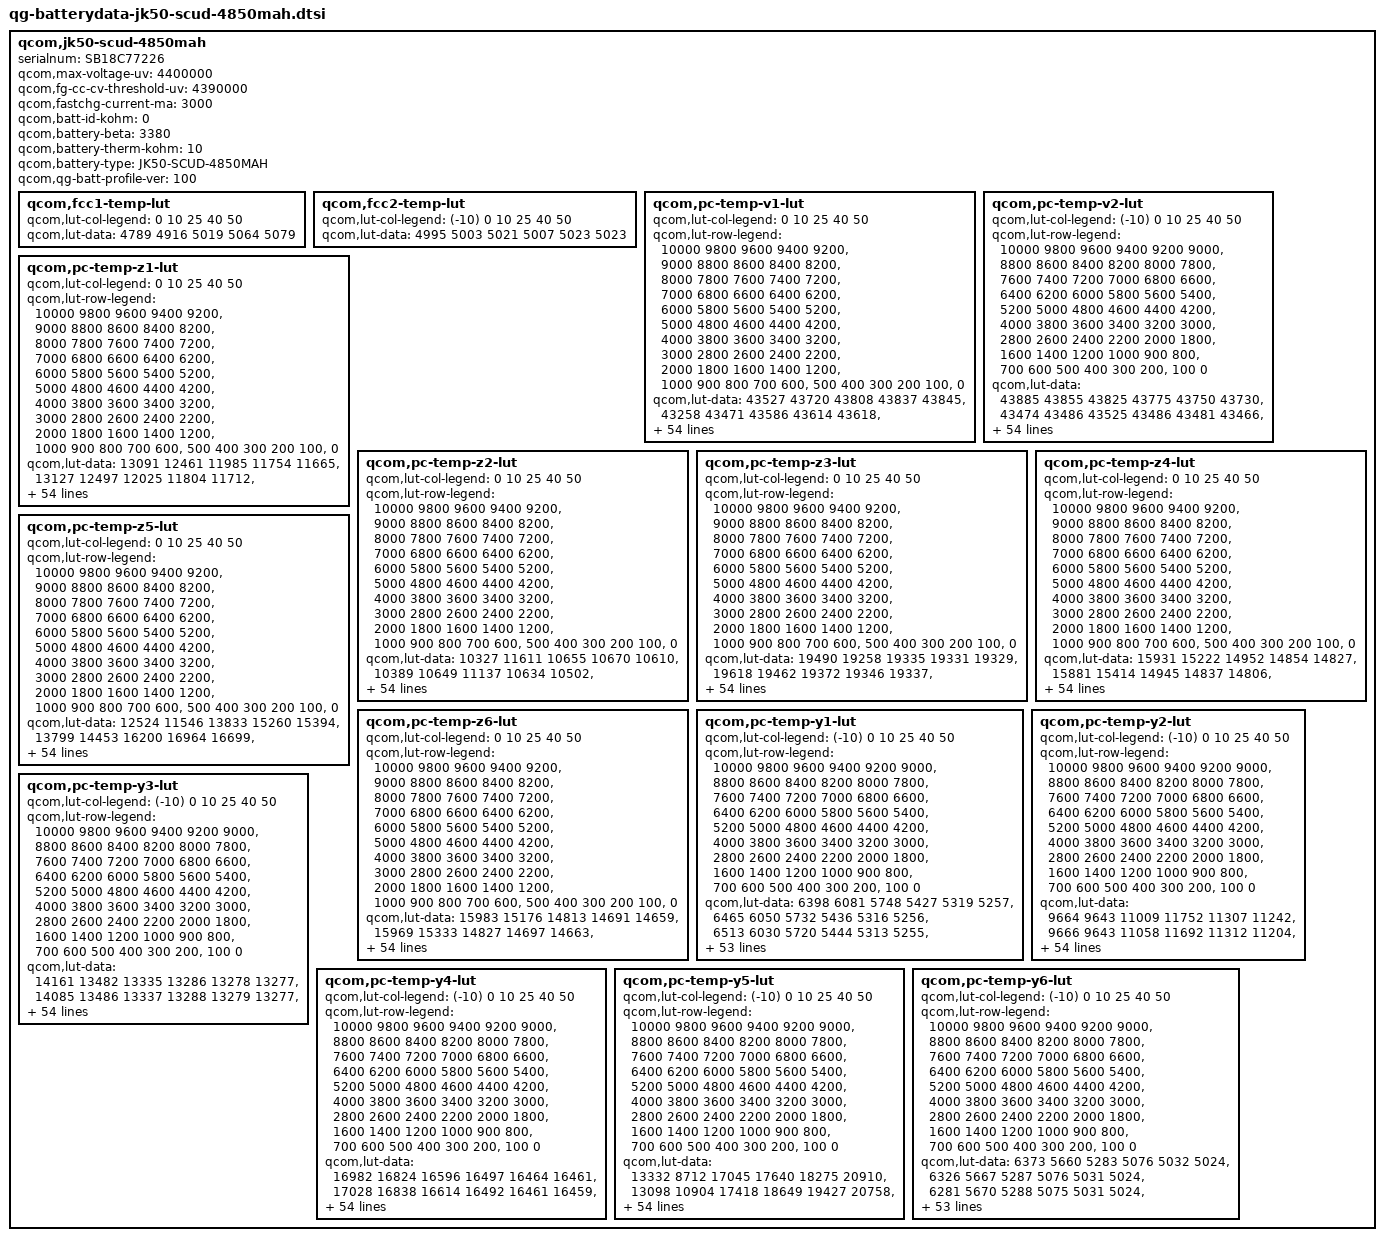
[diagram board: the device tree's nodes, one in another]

qcom,jk50-scud-4850mah {
    /* 4487667_P270AE_SCUD_4850mAH_PMI632_averaged_MasterSlave_Apr8th2020 */
    serialnum = "SB18C77226";
    qcom,max-voltage-uv = <4400000>;
    qcom,fg-cc-cv-threshold-uv = <4390000>;
    qcom,fastchg-current-ma = <3000>;
    qcom,batt-id-kohm = <0>;
    qcom,battery-beta = <3380>;
    qcom,battery-therm-kohm = <10>;
    qcom,battery-type = "JK50-SCUD-4850MAH";
    qcom,qg-batt-profile-ver = <100>;

	qcom,fcc1-temp-lut {
		qcom,lut-col-legend = <0 10 25 40 50>;
		qcom,lut-data = <4789 4916 5019 5064 5079>;
	};

	qcom,fcc2-temp-lut {
		qcom,lut-col-legend = <(-10) 0 10 25 40 50>;
		qcom,lut-data = <4995 5003 5021 5007 5023 5023>;
	};

	qcom,pc-temp-v1-lut {
		qcom,lut-col-legend = <0 10 25 40 50>;
		qcom,lut-row-legend = <10000 9800 9600 9400 9200>,
			<9000 8800 8600 8400 8200>,
			<8000 7800 7600 7400 7200>,
			<7000 6800 6600 6400 6200>,
			<6000 5800 5600 5400 5200>,
			<5000 4800 4600 4400 4200>,
			<4000 3800 3600 3400 3200>,
			<3000 2800 2600 2400 2200>,
			<2000 1800 1600 1400 1200>,
			<1000 900 800 700 600>,
			<500 400 300 200 100>,
			<0>;
		qcom,lut-data = <43527 43720 43808 43837 43845>,
			<43258 43471 43586 43614 43618>,
			<43002 43216 43362 43390 43400>,
			<42761 42969 43124 43158 43170>,
			<42532 42728 42882 42923 42937>,
			<42311 42495 42638 42687 42703>,
			<42098 42267 42393 42451 42467>,
			<41890 42046 42156 42216 42231>,
			<41681 41831 41927 41986 42000>,
			<41477 41616 41703 41759 41771>,
			<41296 41407 41482 41532 41545>,
			<41144 41224 41270 41309 41323>,
			<40970 41074 41086 41094 41105>,
			<40688 40898 40925 40893 40895>,
			<40345 40606 40727 40693 40690>,
			<40100 40268 40429 40483 40490>,
			<39934 40057 40147 40274 40297>,
			<39796 39919 39991 40092 40114>,
			<39671 39796 39877 39933 39942>,
			<39561 39678 39747 39775 39774>,
			<39446 39558 39599 39616 39613>,
			<39327 39402 39425 39445 39447>,
			<39205 39202 39159 39222 39237>,
			<39083 39004 38872 38955 38980>,
			<38959 38805 38724 38778 38797>,
			<38833 38632 38641 38676 38689>,
			<38696 38534 38565 38588 38597>,
			<38570 38469 38486 38491 38494>,
			<38481 38415 38410 38397 38393>,
			<38410 38366 38339 38313 38304>,
			<38357 38324 38272 38239 38226>,
			<38318 38284 38212 38171 38156>,
			<38286 38247 38160 38113 38098>,
			<38256 38213 38112 38059 38043>,
			<38230 38184 38071 38007 37983>,
			<38200 38153 38033 37957 37921>,
			<38169 38119 37993 37907 37860>,
			<38133 38081 37954 37859 37806>,
			<38084 38029 37903 37802 37743>,
			<38017 37944 37821 37719 37655>,
			<37933 37839 37715 37613 37545>,
			<37811 37721 37601 37499 37427>,
			<37668 37584 37472 37368 37295>,
			<37520 37421 37317 37215 37145>,
			<37370 37273 37170 37074 37010>,
			<37258 37172 37081 36991 36932>,
			<37219 37156 37052 36962 36906>,
			<37188 37131 37037 36945 36886>,
			<37162 37107 37019 36927 36865>,
			<37121 37068 36977 36873 36804>,
			<36931 36868 36759 36630 36538>,
			<36501 36442 36338 36197 36097>,
			<35935 35872 35773 35623 35525>,
			<35166 35095 35000 34839 34741>,
			<33969 33890 33810 33627 33524>,
			<30000 30000 30000 30000 30000>;
	};

	qcom,pc-temp-v2-lut {
		qcom,lut-col-legend = <(-10) 0 10 25 40 50>;
		qcom,lut-row-legend = <10000 9800 9600 9400 9200 9000>,
			<8800 8600 8400 8200 8000 7800>,
			<7600 7400 7200 7000 6800 6600>,
			<6400 6200 6000 5800 5600 5400>,
			<5200 5000 4800 4600 4400 4200>,
			<4000 3800 3600 3400 3200 3000>,
			<2800 2600 2400 2200 2000 1800>,
			<1600 1400 1200 1000 900 800>,
			<700 600 500 400 300 200>,
			<100 0>;
		qcom,lut-data = <43885 43855 43825 43775 43750 43730>,
			<43474 43486 43525 43486 43481 43466>,
			<43101 43156 43244 43213 43220 43210>,
			<42770 42871 42981 42957 42972 42964>,
			<42473 42624 42736 42717 42733 42728>,
			<42205 42382 42495 42481 42497 42493>,
			<41960 42137 42255 42245 42261 42259>,
			<41736 41892 42019 42013 42027 42026>,
			<41509 41621 41791 41785 41798 41796>,
			<41289 41340 41569 41562 41571 41568>,
			<41193 41168 41355 41340 41347 41344>,
			<41169 41084 41147 41118 41127 41125>,
			<41140 40990 40949 40907 40912 40909>,
			<40792 40780 40773 40726 40711 40701>,
			<40103 40467 40599 40555 40515 40498>,
			<39725 40162 40365 40343 40318 40304>,
			<39532 39838 40047 40073 40119 40118>,
			<39362 39565 39780 39851 39934 39939>,
			<39182 39386 39612 39721 39773 39774>,
			<39009 39231 39462 39606 39613 39608>,
			<38840 39046 39273 39425 39417 39417>,
			<38671 38841 39059 39173 39192 39202>,
			<38532 38659 38872 38951 38984 38998>,
			<38418 38495 38711 38767 38791 38799>,
			<38324 38357 38569 38610 38624 38626>,
			<38250 38254 38445 38486 38497 38496>,
			<38189 38172 38335 38383 38391 38389>,
			<38132 38109 38232 38287 38292 38289>,
			<38080 38058 38136 38197 38202 38197>,
			<38031 38015 38050 38114 38120 38113>,
			<37982 37974 37975 38040 38048 38040>,
			<37933 37936 37910 37971 37982 37972>,
			<37884 37898 37865 37908 37918 37908>,
			<37836 37861 37831 37850 37856 37848>,
			<37785 37822 37798 37795 37789 37779>,
			<37731 37781 37763 37741 37710 37689>,
			<37672 37737 37726 37686 37627 37592>,
			<37607 37684 37681 37625 37544 37495>,
			<37536 37622 37628 37559 37459 37397>,
			<37461 37550 37561 37486 37378 37310>,
			<37383 37467 37469 37404 37302 37236>,
			<37304 37367 37359 37308 37213 37148>,
			<37224 37244 37232 37191 37101 37037>,
			<37151 37109 37090 37057 36961 36895>,
			<37068 36991 36961 36929 36848 36791>,
			<36983 36913 36901 36883 36815 36760>,
			<36938 36889 36875 36868 36803 36748>,
			<36884 36860 36851 36854 36787 36735>,
			<36807 36816 36811 36827 36763 36705>,
			<36680 36728 36722 36764 36676 36605>,
			<36437 36508 36478 36532 36379 36279>,
			<36026 36071 36010 36064 35878 35774>,
			<35432 35443 35368 35447 35228 35115>,
			<34574 34550 34458 34598 34326 34193>,
			<33175 33170 33140 33334 32948 32812>,
			<28986 28473 27920 28444 28011 28001>;
	};

	qcom,pc-temp-z1-lut {
		qcom,lut-col-legend = <0 10 25 40 50>;
		qcom,lut-row-legend = <10000 9800 9600 9400 9200>,
			<9000 8800 8600 8400 8200>,
			<8000 7800 7600 7400 7200>,
			<7000 6800 6600 6400 6200>,
			<6000 5800 5600 5400 5200>,
			<5000 4800 4600 4400 4200>,
			<4000 3800 3600 3400 3200>,
			<3000 2800 2600 2400 2200>,
			<2000 1800 1600 1400 1200>,
			<1000 900 800 700 600>,
			<500 400 300 200 100>,
			<0>;
		qcom,lut-data = <13091 12461 11985 11754 11665>,
			<13127 12497 12025 11804 11712>,
			<13151 12516 12024 11806 11719>,
			<13165 12519 12036 11801 11720>,
			<13170 12509 12044 11798 11719>,
			<13163 12499 12040 11796 11717>,
			<13148 12496 12032 11793 11717>,
			<13138 12501 12026 11790 11716>,
			<13144 12505 12021 11789 11717>,
			<13150 12503 12018 11788 11719>,
			<13150 12498 12020 11787 11721>,
			<13157 12494 12023 11787 11722>,
			<13162 12489 12022 11786 11722>,
			<13130 12483 12017 11785 11721>,
			<13073 12460 12011 11784 11720>,
			<13056 12430 12001 11782 11720>,
			<13055 12424 11993 11781 11720>,
			<13055 12425 11996 11781 11720>,
			<13059 12428 12004 11783 11722>,
			<13066 12437 12010 11784 11722>,
			<13067 12450 12014 11784 11722>,
			<13058 12457 12017 11784 11722>,
			<13048 12462 12020 11785 11722>,
			<13046 12465 12023 11787 11723>,
			<13046 12469 12025 11788 11725>,
			<13049 12473 12028 11791 11726>,
			<13060 12477 12030 11794 11727>,
			<13070 12485 12031 11797 11730>,
			<13072 12491 12032 11801 11733>,
			<13071 12497 12036 11804 11736>,
			<13073 12501 12042 11808 11738>,
			<13086 12503 12047 11812 11741>,
			<13101 12503 12053 11815 11744>,
			<13106 12503 12057 11818 11747>,
			<13110 12505 12058 11823 11751>,
			<13117 12508 12059 11827 11755>,
			<13133 12511 12062 11831 11758>,
			<13148 12516 12070 11833 11760>,
			<13158 12523 12077 11836 11763>,
			<13178 12540 12078 11840 11766>,
			<13191 12556 12079 11844 11769>,
			<13201 12563 12081 11848 11772>,
			<13207 12567 12087 11852 11776>,
			<13211 12569 12093 11857 11778>,
			<13202 12573 12104 11863 11780>,
			<13197 12571 12106 11866 11783>,
			<13165 12566 12106 11869 11783>,
			<13192 12574 12106 11870 11784>,
			<13186 12571 12103 11870 11787>,
			<13194 12588 12114 11874 11792>,
			<13185 12574 12115 11881 11798>,
			<13221 12597 12127 11889 11805>,
			<13214 12609 12142 11901 11818>,
			<13253 12651 12178 11918 11834>,
			<13253 12651 12178 11918 11834>,
			<13253 12651 12178 11918 11834>;
	};

	qcom,pc-temp-z2-lut {
		qcom,lut-col-legend = <0 10 25 40 50>;
		qcom,lut-row-legend = <10000 9800 9600 9400 9200>,
			<9000 8800 8600 8400 8200>,
			<8000 7800 7600 7400 7200>,
			<7000 6800 6600 6400 6200>,
			<6000 5800 5600 5400 5200>,
			<5000 4800 4600 4400 4200>,
			<4000 3800 3600 3400 3200>,
			<3000 2800 2600 2400 2200>,
			<2000 1800 1600 1400 1200>,
			<1000 900 800 700 600>,
			<500 400 300 200 100>,
			<0>;
		qcom,lut-data = <10327 11611 10655 10670 10610>,
			<10389 10649 11137 10634 10502>,
			<10422 10668 12508 10705 10487>,
			<10425 10685 12606 10742 10605>,
			<10424 10664 12430 10744 10603>,
			<10427 10629 11777 10731 10598>,
			<10432 10599 10968 10702 10605>,
			<10434 10573 10755 10669 10605>,
			<10430 10552 10717 10622 10575>,
			<10422 10537 10707 10580 10528>,
			<10417 10525 10899 10584 10507>,
			<10415 10549 11126 10604 10505>,
			<10412 10721 11181 10605 10500>,
			<10372 10842 11344 10531 10466>,
			<10307 10761 11389 10470 10422>,
			<10290 10626 11088 10516 10390>,
			<10296 10601 10788 10597 10362>,
			<10307 10615 10748 10596 10359>,
			<10327 10637 10733 10508 10380>,
			<10358 10675 10736 10459 10407>,
			<10381 10722 10786 10558 10441>,
			<10397 10757 10829 10678 10475>,
			<10411 10787 10840 10647 10480>,
			<10425 10798 10842 10527 10477>,
			<10440 10774 10827 10487 10478>,
			<10457 10744 10782 10516 10499>,
			<10479 10747 10760 10568 10537>,
			<10502 10767 10793 10718 10641>,
			<10521 10777 10838 10919 10792>,
			<10537 10777 10857 10935 10804>,
			<10552 10777 10869 10826 10671>,
			<10562 10781 10876 10731 10530>,
			<10573 10790 10883 10664 10404>,
			<10588 10802 10889 10621 10312>,
			<10610 10817 10895 10623 10318>,
			<10636 10835 10905 10640 10367>,
			<10673 10852 10918 10664 10420>,
			<10707 10869 10938 10720 10479>,
			<10645 10887 10964 10781 10537>,
			<10407 10911 11015 10830 10583>,
			<10300 10933 11065 10872 10622>,
			<10337 10945 11067 10896 10645>,
			<10379 10957 11058 10917 10663>,
			<10127 10987 11064 10931 10704>,
			<10154 11156 11103 10920 10727>,
			<10555 11339 11168 10784 10601>,
			<10427 11087 11164 10779 10604>,
			<10647 16175 11150 10794 10608>,
			<10616 12280 11151 10834 10665>,
			<10602 11569 11225 10941 10777>,
			<10594 11472 11279 10867 10597>,
			<10227 11135 11216 10661 10387>,
			<10074 11040 11194 10600 10302>,
			<9765 10768 11064 10537 10252>,
			<9765 10768 11064 10537 10252>,
			<9765 10768 11064 10537 10252>;
	};

	qcom,pc-temp-z3-lut {
		qcom,lut-col-legend = <0 10 25 40 50>;
		qcom,lut-row-legend = <10000 9800 9600 9400 9200>,
			<9000 8800 8600 8400 8200>,
			<8000 7800 7600 7400 7200>,
			<7000 6800 6600 6400 6200>,
			<6000 5800 5600 5400 5200>,
			<5000 4800 4600 4400 4200>,
			<4000 3800 3600 3400 3200>,
			<3000 2800 2600 2400 2200>,
			<2000 1800 1600 1400 1200>,
			<1000 900 800 700 600>,
			<500 400 300 200 100>,
			<0>;
		qcom,lut-data = <19490 19258 19335 19331 19329>,
			<19618 19462 19372 19346 19337>,
			<19688 19511 19386 19370 19345>,
			<19707 19546 19413 19384 19371>,
			<19718 19552 19430 19389 19378>,
			<19717 19554 19434 19393 19384>,
			<19703 19554 19436 19398 19391>,
			<19686 19550 19436 19400 19394>,
			<19675 19544 19436 19399 19394>,
			<19663 19540 19435 19396 19393>,
			<19648 19534 19439 19393 19391>,
			<19624 19532 19441 19389 19386>,
			<19609 19531 19441 19384 19381>,
			<19639 19530 19439 19375 19375>,
			<19696 19530 19436 19369 19371>,
			<19709 19530 19433 19371 19368>,
			<19674 19525 19428 19375 19365>,
			<19634 19501 19417 19374 19362>,
			<19608 19481 19400 19365 19358>,
			<19586 19472 19394 19359 19355>,
			<19580 19465 19393 19358 19352>,
			<19581 19469 19392 19357 19349>,
			<19583 19491 19397 19356 19344>,
			<19588 19504 19406 19353 19337>,
			<19600 19505 19405 19348 19332>,
			<19611 19505 19393 19338 19329>,
			<19624 19505 19387 19332 19327>,
			<19633 19503 19387 19347 19347>,
			<19633 19501 19388 19376 19389>,
			<19627 19498 19393 19385 19397>,
			<19620 19495 19403 19389 19393>,
			<19610 19492 19408 19390 19387>,
			<19598 19489 19410 19385 19377>,
			<19586 19486 19411 19378 19366>,
			<19573 19484 19409 19372 19359>,
			<19561 19481 19405 19365 19353>,
			<19551 19478 19401 19360 19348>,
			<19539 19475 19396 19355 19344>,
			<19506 19472 19393 19352 19341>,
			<19436 19469 19391 19349 19339>,
			<19400 19465 19389 19347 19338>,
			<19398 19460 19386 19348 19340>,
			<19395 19454 19382 19351 19346>,
			<19303 19448 19380 19352 19349>,
			<19262 19427 19376 19351 19349>,
			<19260 19402 19361 19335 19335>,
			<19261 19300 19360 19335 19329>,
			<19260 19284 19347 19329 19323>,
			<19260 19276 19342 19325 19317>,
			<19260 19277 19336 19319 19312>,
			<19260 19281 19344 19333 19339>,
			<19261 19283 19342 19340 19350>,
			<19262 19282 19328 19341 19347>,
			<19265 19282 19325 19339 19345>,
			<19265 19282 19325 19339 19345>,
			<19265 19282 19325 19339 19345>;
	};

	qcom,pc-temp-z4-lut {
		qcom,lut-col-legend = <0 10 25 40 50>;
		qcom,lut-row-legend = <10000 9800 9600 9400 9200>,
			<9000 8800 8600 8400 8200>,
			<8000 7800 7600 7400 7200>,
			<7000 6800 6600 6400 6200>,
			<6000 5800 5600 5400 5200>,
			<5000 4800 4600 4400 4200>,
			<4000 3800 3600 3400 3200>,
			<3000 2800 2600 2400 2200>,
			<2000 1800 1600 1400 1200>,
			<1000 900 800 700 600>,
			<500 400 300 200 100>,
			<0>;
		qcom,lut-data = <15931 15222 14952 14854 14827>,
			<15881 15414 14945 14837 14806>,
			<15798 15320 15012 14863 14809>,
			<15655 15193 14945 14868 14841>,
			<15478 15100 14870 14834 14818>,
			<15353 15015 14840 14806 14795>,
			<15259 14951 14820 14783 14775>,
			<15185 14901 14798 14762 14756>,
			<15130 14862 14775 14745 14739>,
			<15085 14836 14751 14730 14724>,
			<15044 14815 14727 14718 14713>,
			<15006 14783 14703 14707 14706>,
			<14970 14730 14682 14700 14700>,
			<14932 14700 14654 14696 14695>,
			<14897 14718 14644 14692 14692>,
			<14876 14747 14680 14687 14688>,
			<14864 14752 14716 14682 14684>,
			<14853 14740 14706 14677 14679>,
			<14839 14727 14681 14670 14674>,
			<14823 14714 14673 14667 14672>,
			<14807 14703 14674 14669 14674>,
			<14789 14704 14677 14674 14679>,
			<14773 14719 14733 14709 14708>,
			<14759 14738 14820 14795 14790>,
			<14748 14780 14833 14824 14823>,
			<14744 14821 14823 14819 14816>,
			<14752 14821 14811 14810 14802>,
			<14761 14804 14795 14782 14765>,
			<14763 14786 14776 14739 14709>,
			<14764 14771 14757 14715 14689>,
			<14763 14757 14736 14699 14683>,
			<14758 14745 14721 14689 14679>,
			<14752 14734 14708 14682 14675>,
			<14749 14724 14700 14678 14672>,
			<14746 14715 14696 14678 14672>,
			<14743 14707 14693 14679 14673>,
			<14741 14700 14691 14679 14674>,
			<14740 14695 14689 14679 14674>,
			<14760 14694 14689 14679 14674>,
			<14827 14695 14693 14686 14682>,
			<14859 14697 14698 14697 14695>,
			<14856 14695 14696 14696 14696>,
			<14851 14692 14689 14688 14688>,
			<14932 14689 14687 14688 14689>,
			<14923 14681 14679 14687 14688>,
			<14878 14666 14657 14666 14665>,
			<14874 14770 14650 14660 14663>,
			<14869 14780 14651 14649 14653>,
			<14864 14782 14646 14634 14635>,
			<14859 14778 14648 14635 14632>,
			<14860 14781 14657 14652 14646>,
			<14879 14790 14669 14660 14654>,
			<14889 14796 14688 14664 14661>,
			<14903 14806 14697 14669 14665>,
			<14903 14806 14697 14669 14665>,
			<14903 14806 14697 14669 14665>;
	};

	qcom,pc-temp-z5-lut {
		qcom,lut-col-legend = <0 10 25 40 50>;
		qcom,lut-row-legend = <10000 9800 9600 9400 9200>,
			<9000 8800 8600 8400 8200>,
			<8000 7800 7600 7400 7200>,
			<7000 6800 6600 6400 6200>,
			<6000 5800 5600 5400 5200>,
			<5000 4800 4600 4400 4200>,
			<4000 3800 3600 3400 3200>,
			<3000 2800 2600 2400 2200>,
			<2000 1800 1600 1400 1200>,
			<1000 900 800 700 600>,
			<500 400 300 200 100>,
			<0>;
		qcom,lut-data = <12524 11546 13833 15260 15394>,
			<13799 14453 16200 16964 16699>,
			<14681 15700 15700 18448 17559>,
			<15223 16924 16546 19029 19341>,
			<15609 17733 17543 19666 20255>,
			<15829 18369 18660 20417 21258>,
			<15965 18977 19948 21463 22671>,
			<16084 19580 20930 22269 24080>,
			<16240 20128 21780 22659 25257>,
			<16379 20662 22770 23059 26241>,
			<16364 21340 24791 23808 26892>,
			<16142 22351 27299 24920 27595>,
			<15993 24190 30073 25214 27930>,
			<18258 26296 34719 24305 27890>,
			<22488 29020 36682 23545 27963>,
			<23442 31578 35248 25995 28668>,
			<21305 31032 32943 30570 30000>,
			<19261 26423 30266 31273 31350>,
			<18767 23733 27318 30042 32902>,
			<18496 24159 26998 29355 33810>,
			<18508 25262 30449 30951 33893>,
			<19595 30663 34482 32907 33633>,
			<21488 47924 38322 31977 31714>,
			<24104 56943 41764 28112 25756>,
			<28277 54745 40175 24218 21110>,
			<33648 50818 30592 19733 17926>,
			<43024 47257 24627 17085 16167>,
			<50585 43344 23316 18515 19521>,
			<50792 40411 22663 21827 27007>,
			<49025 38327 23450 24751 30609>,
			<46657 36834 26349 27782 32555>,
			<42588 36259 29586 30227 33272>,
			<37839 36498 33612 32132 31773>,
			<34211 37230 37229 33494 29898>,
			<30986 38331 39755 34131 30329>,
			<28602 39209 41699 34546 32060>,
			<27086 39861 41859 34573 32597>,
			<25728 40922 40763 33847 31830>,
			<23459 41115 39666 32673 30700>,
			<20113 40701 38467 30395 28449>,
			<18619 39993 36801 27651 25629>,
			<18834 37714 34474 26808 25441>,
			<19064 34611 31665 26840 26800>,
			<14011 33741 31342 27468 28023>,
			<12141 31978 32061 27651 28322>,
			<12271 29890 30794 23935 23905>,
			<12252 14462 30675 24086 21186>,
			<12229 13103 24723 23487 20712>,
			<12226 12762 23699 25108 23171>,
			<12241 12829 22199 22979 22331>,
			<12329 13054 22718 22538 26099>,
			<12222 12946 19929 20522 24429>,
			<12097 12765 16474 19155 20367>,
			<11962 12546 15615 17555 17690>,
			<11962 12546 15615 17555 17690>,
			<11962 12546 15615 17555 17690>;
	};

	qcom,pc-temp-z6-lut {
		qcom,lut-col-legend = <0 10 25 40 50>;
		qcom,lut-row-legend = <10000 9800 9600 9400 9200>,
			<9000 8800 8600 8400 8200>,
			<8000 7800 7600 7400 7200>,
			<7000 6800 6600 6400 6200>,
			<6000 5800 5600 5400 5200>,
			<5000 4800 4600 4400 4200>,
			<4000 3800 3600 3400 3200>,
			<3000 2800 2600 2400 2200>,
			<2000 1800 1600 1400 1200>,
			<1000 900 800 700 600>,
			<500 400 300 200 100>,
			<0>;
		qcom,lut-data = <15983 15176 14813 14691 14659>,
			<15969 15333 14827 14697 14663>,
			<15937 15296 14862 14721 14669>,
			<15860 15242 14842 14727 14693>,
			<15748 15192 14819 14717 14689>,
			<15662 15140 14805 14708 14685>,
			<15593 15097 14792 14699 14680>,
			<15534 15063 14779 14691 14674>,
			<15488 15034 14766 14683 14668>,
			<15449 15011 14755 14675 14661>,
			<15409 14993 14746 14668 14655>,
			<15366 14969 14738 14661 14649>,
			<15333 14938 14727 14655 14643>,
			<15317 14920 14712 14648 14638>,
			<15307 14920 14706 14642 14634>,
			<15290 14922 14716 14641 14630>,
			<15259 14919 14725 14641 14627>,
			<15228 14901 14717 14638 14623>,
			<15205 14886 14698 14630 14618>,
			<15186 14879 14692 14625 14615>,
			<15177 14873 14693 14626 14615>,
			<15172 14876 14694 14627 14616>,
			<15169 14894 14722 14641 14625>,
			<15170 14914 14765 14677 14657>,
			<15175 14935 14770 14688 14669>,
			<15181 14952 14761 14682 14664>,
			<15194 14952 14753 14675 14658>,
			<15206 14946 14746 14672 14655>,
			<15207 14939 14741 14669 14653>,
			<15207 14932 14737 14665 14650>,
			<15206 14926 14734 14661 14646>,
			<15201 14921 14731 14657 14641>,
			<15194 14916 14729 14652 14634>,
			<15189 14912 14726 14648 14627>,
			<15184 14909 14724 14644 14624>,
			<15181 14907 14722 14642 14622>,
			<15178 14906 14720 14639 14619>,
			<15176 14905 14718 14637 14616>,
			<15174 14905 14717 14635 14615>,
			<15173 14908 14719 14638 14617>,
			<15174 14912 14722 14642 14622>,
			<15179 14913 14721 14642 14624>,
			<15183 14913 14718 14641 14625>,
			<15180 14914 14719 14642 14627>,
			<15166 14909 14717 14642 14627>,
			<15154 14896 14703 14626 14610>,
			<15150 14889 14700 14623 14606>,
			<15151 14887 14694 14616 14598>,
			<15148 14885 14689 14607 14588>,
			<15154 14889 14690 14606 14585>,
			<15161 14897 14701 14622 14606>,
			<15178 14908 14709 14631 14618>,
			<15194 14920 14715 14636 14623>,
			<15222 14937 14724 14642 14627>,
			<15222 14937 14724 14642 14627>,
			<15222 14937 14724 14642 14627>;
	};

	qcom,pc-temp-y1-lut {
		qcom,lut-col-legend = <(-10) 0 10 25 40 50>;
		qcom,lut-row-legend = <10000 9800 9600 9400 9200 9000>,
			<8800 8600 8400 8200 8000 7800>,
			<7600 7400 7200 7000 6800 6600>,
			<6400 6200 6000 5800 5600 5400>,
			<5200 5000 4800 4600 4400 4200>,
			<4000 3800 3600 3400 3200 3000>,
			<2800 2600 2400 2200 2000 1800>,
			<1600 1400 1200 1000 900 800>,
			<700 600 500 400 300 200>,
			<100 0>;
		qcom,lut-data = <6398 6081 5748 5427 5319 5257>,
			<6465 6050 5732 5436 5316 5256>,
			<6513 6030 5720 5444 5313 5255>,
			<6545 6018 5710 5450 5310 5254>,
			<6561 6014 5705 5453 5307 5253>,
			<6565 6013 5704 5454 5305 5252>,
			<6544 6024 5709 5452 5303 5250>,
			<6520 6035 5714 5449 5301 5249>,
			<6522 6031 5712 5445 5300 5248>,
			<6532 6018 5708 5441 5297 5248>,
			<6539 6015 5704 5440 5296 5248>,
			<6559 6028 5698 5440 5295 5246>,
			<6576 6038 5694 5441 5294 5245>,
			<6573 6034 5695 5439 5292 5244>,
			<6567 6027 5698 5435 5290 5244>,
			<6568 6028 5705 5435 5290 5243>,
			<6581 6041 5720 5439 5291 5243>,
			<6590 6052 5727 5442 5292 5243>,
			<6568 6057 5721 5442 5290 5243>,
			<6535 6062 5712 5443 5289 5243>,
			<6531 6061 5714 5443 5289 5243>,
			<6536 6059 5720 5446 5289 5243>,
			<6543 6058 5722 5447 5290 5243>,
			<6564 6054 5718 5448 5291 5244>,
			<6584 6051 5713 5448 5293 5246>,
			<6574 6055 5714 5448 5295 5247>,
			<6546 6065 5717 5448 5296 5248>,
			<6538 6069 5718 5448 5298 5250>,
			<6554 6058 5713 5452 5301 5251>,
			<6566 6048 5709 5455 5304 5253>,
			<6554 6047 5716 5457 5306 5256>,
			<6535 6045 5723 5458 5308 5258>,
			<6529 6042 5723 5461 5311 5260>,
			<6528 6038 5721 5467 5314 5262>,
			<6526 6037 5720 5471 5317 5264>,
			<6525 6038 5720 5471 5320 5265>,
			<6526 6039 5722 5472 5323 5267>,
			<6530 6042 5723 5474 5324 5269>,
			<6538 6045 5725 5477 5324 5271>,
			<6540 6045 5727 5481 5325 5273>,
			<6540 6047 5726 5484 5328 5274>,
			<6540 6052 5726 5484 5331 5276>,
			<6562 6063 5733 5482 5333 5278>,
			<6556 6061 5730 5488 5337 5282>,
			<6555 6072 5736 5496 5343 5286>,
			<6573 6062 5742 5498 5350 5290>,
			<6578 6097 5750 5503 5348 5288>,
			<6599 6089 5740 5511 5348 5287>,
			<6628 6078 5742 5506 5347 5287>,
			<6574 6094 5744 5499 5345 5287>,
			<6589 6097 5760 5504 5347 5290>,
			<6621 6118 5753 5515 5355 5295>,
			<6602 6123 5767 5526 5365 5302>,
			<6665 6127 5791 5534 5372 5312>,
			<6665 6127 5791 5534 5372 5312>,
			<6665 6127 5791 5534 5372 5312>;
	};

	qcom,pc-temp-y2-lut {
		qcom,lut-col-legend = <(-10) 0 10 25 40 50>;
		qcom,lut-row-legend = <10000 9800 9600 9400 9200 9000>,
			<8800 8600 8400 8200 8000 7800>,
			<7600 7400 7200 7000 6800 6600>,
			<6400 6200 6000 5800 5600 5400>,
			<5200 5000 4800 4600 4400 4200>,
			<4000 3800 3600 3400 3200 3000>,
			<2800 2600 2400 2200 2000 1800>,
			<1600 1400 1200 1000 900 800>,
			<700 600 500 400 300 200>,
			<100 0>;
		qcom,lut-data = <9664 9643 11009 11752 11307 11242>,
			<9666 9643 11058 11692 11312 11204>,
			<9668 9897 11089 11635 11294 11167>,
			<9669 10183 11104 11582 11262 11132>,
			<9671 10372 11108 11534 11226 11099>,
			<9673 10426 11104 11491 11195 11068>,
			<9674 10326 11081 11452 11149 11034>,
			<9676 10215 11055 11419 11108 11009>,
			<9675 10304 11045 11391 11097 11002>,
			<9672 10561 11041 11367 11088 10999>,
			<9671 10640 11024 11342 11080 10989>,
			<9673 10559 10972 11312 11065 10946>,
			<9673 10492 10935 11289 11053 10913>,
			<9672 10561 11110 11278 11057 10917>,
			<9670 10709 11409 11272 11071 10927>,
			<9670 10750 11457 11294 11091 10946>,
			<9670 10550 11419 11411 11144 10998>,
			<9670 10423 11399 11530 11214 11059>,
			<9670 10470 11433 11629 11366 11137>,
			<9669 10507 11481 11701 11520 11226>,
			<9669 10370 11500 11704 11552 11319>,
			<9669 9926 11514 11687 11557 11415>,
			<9669 9729 11529 11677 11542 11436>,
			<9668 9711 11558 11674 11465 11332>,
			<9668 9703 11591 11676 11404 11242>,
			<9667 9703 11626 11693 11443 11262>,
			<9667 9703 11662 11731 11527 11315>,
			<9666 9702 11671 11769 11546 11346>,
			<9666 9698 11655 11812 11538 11370>,
			<9666 9692 11645 11850 11533 11398>,
			<9665 9687 11665 11881 11573 11433>,
			<9665 9682 11688 11905 11642 11479>,
			<9665 9678 11677 11915 11690 11556>,
			<9664 9675 11619 11913 11741 11674>,
			<9664 9672 11564 11903 11754 11715>,
			<9664 9670 11521 11869 11715 11641>,
			<9663 9668 11474 11826 11674 11537>,
			<9663 9667 11416 11797 11651 11451>,
			<9663 9665 11348 11770 11616 11369>,
			<9663 9664 11226 11741 11591 11359>,
			<9663 9663 10782 11705 11564 11421>,
			<9663 9662 10310 11672 11572 11433>,
			<9662 9662 9804 11636 11608 11385>,
			<9662 9661 9734 11551 11457 11309>,
			<9662 9662 9717 11532 11478 11214>,
			<9662 9661 9701 11460 11276 11056>,
			<9662 9661 9695 11416 11288 11032>,
			<9662 9660 9688 11397 11337 11086>,
			<9661 9660 9683 11381 11387 11155>,
			<9661 9660 9680 11385 11374 11087>,
			<9661 9659 9677 11345 11297 10978>,
			<9660 9659 9673 11253 11197 10919>,
			<9660 9659 9668 11126 11083 10809>,
			<9659 9658 9664 11023 10967 10659>,
			<9659 9658 9664 11023 10967 10659>,
			<9659 9658 9664 11023 10967 10659>;
	};

	qcom,pc-temp-y3-lut {
		qcom,lut-col-legend = <(-10) 0 10 25 40 50>;
		qcom,lut-row-legend = <10000 9800 9600 9400 9200 9000>,
			<8800 8600 8400 8200 8000 7800>,
			<7600 7400 7200 7000 6800 6600>,
			<6400 6200 6000 5800 5600 5400>,
			<5200 5000 4800 4600 4400 4200>,
			<4000 3800 3600 3400 3200 3000>,
			<2800 2600 2400 2200 2000 1800>,
			<1600 1400 1200 1000 900 800>,
			<700 600 500 400 300 200>,
			<100 0>;
		qcom,lut-data = <14161 13482 13335 13286 13278 13277>,
			<14085 13486 13337 13288 13279 13277>,
			<14010 13489 13339 13289 13279 13278>,
			<13940 13489 13341 13291 13281 13278>,
			<13881 13487 13343 13292 13281 13279>,
			<13837 13484 13345 13293 13282 13280>,
			<13809 13476 13348 13293 13282 13280>,
			<13782 13470 13349 13293 13282 13281>,
			<13715 13471 13349 13294 13282 13281>,
			<13611 13476 13349 13295 13283 13282>,
			<13578 13473 13349 13295 13283 13282>,
			<13582 13412 13355 13295 13284 13283>,
			<13585 13360 13360 13295 13284 13283>,
			<13582 13373 13353 13299 13287 13284>,
			<13574 13401 13342 13306 13291 13284>,
			<13562 13406 13339 13307 13292 13284>,
			<13539 13394 13339 13301 13290 13287>,
			<13525 13383 13338 13297 13290 13289>,
			<13523 13379 13335 13298 13290 13290>,
			<13522 13375 13331 13300 13291 13290>,
			<13522 13369 13327 13299 13290 13289>,
			<13521 13360 13322 13296 13287 13286>,
			<13522 13351 13317 13293 13283 13282>,
			<13527 13339 13314 13289 13281 13279>,
			<13533 13328 13312 13285 13279 13277>,
			<13543 13321 13310 13286 13278 13277>,
			<13560 13316 13309 13287 13278 13277>,
			<13578 13315 13308 13287 13278 13277>,
			<13600 13322 13307 13287 13277 13276>,
			<13624 13333 13305 13287 13276 13275>,
			<13649 13348 13301 13286 13277 13275>,
			<13675 13370 13296 13286 13277 13275>,
			<13705 13393 13297 13287 13278 13276>,
			<13739 13419 13301 13287 13279 13277>,
			<13774 13448 13305 13287 13279 13277>,
			<13810 13480 13308 13287 13279 13277>,
			<13846 13517 13310 13286 13279 13277>,
			<13880 13558 13313 13287 13278 13277>,
			<13913 13604 13315 13287 13277 13276>,
			<13944 13653 13317 13287 13278 13276>,
			<13973 13704 13316 13287 13280 13279>,
			<14001 13755 13319 13288 13281 13280>,
			<14029 13804 13328 13289 13281 13280>,
			<14057 13847 13332 13288 13278 13276>,
			<14027 13833 13326 13285 13275 13275>,
			<14105 13923 13349 13290 13281 13282>,
			<14154 13971 13356 13292 13284 13285>,
			<14197 14019 13372 13297 13288 13288>,
			<14243 14068 13396 13301 13292 13289>,
			<14297 14103 13416 13305 13291 13287>,
			<14352 14139 13435 13302 13286 13284>,
			<14422 14181 13466 13301 13285 13284>,
			<14520 14269 13537 13307 13289 13286>,
			<14675 14368 13635 13314 13297 13293>,
			<14675 14368 13635 13314 13297 13293>,
			<14675 14368 13635 13314 13297 13293>;
	};

	qcom,pc-temp-y4-lut {
		qcom,lut-col-legend = <(-10) 0 10 25 40 50>;
		qcom,lut-row-legend = <10000 9800 9600 9400 9200 9000>,
			<8800 8600 8400 8200 8000 7800>,
			<7600 7400 7200 7000 6800 6600>,
			<6400 6200 6000 5800 5600 5400>,
			<5200 5000 4800 4600 4400 4200>,
			<4000 3800 3600 3400 3200 3000>,
			<2800 2600 2400 2200 2000 1800>,
			<1600 1400 1200 1000 900 800>,
			<700 600 500 400 300 200>,
			<100 0>;
		qcom,lut-data = <16982 16824 16596 16497 16464 16461>,
			<17028 16838 16614 16492 16461 16459>,
			<17076 16855 16634 16489 16458 16458>,
			<17118 16872 16653 16487 16457 16457>,
			<17147 16887 16666 16486 16457 16457>,
			<17156 16897 16670 16486 16457 16457>,
			<17144 16913 16665 16487 16459 16457>,
			<17131 16926 16661 16489 16461 16457>,
			<17183 16909 16664 16492 16463 16458>,
			<17354 16861 16673 16496 16466 16460>,
			<17505 16870 16678 16501 16469 16462>,
			<17647 17171 16680 16507 16473 16464>,
			<17731 17425 16683 16514 16477 16468>,
			<17494 17337 16756 16528 16481 16472>,
			<17021 17132 16876 16547 16484 16477>,
			<16893 16983 16873 16558 16490 16482>,
			<16883 16855 16753 16565 16500 16485>,
			<16873 16794 16685 16574 16512 16491>,
			<16850 16791 16689 16607 16536 16509>,
			<16819 16790 16695 16642 16557 16527>,
			<16782 16775 16675 16630 16554 16527>,
			<16735 16730 16617 16568 16536 16522>,
			<16711 16688 16577 16520 16514 16514>,
			<16704 16646 16554 16491 16481 16483>,
			<16701 16617 16539 16474 16458 16458>,
			<16700 16617 16531 16473 16458 16457>,
			<16700 16620 16525 16472 16459 16456>,
			<16700 16623 16517 16473 16461 16457>,
			<16701 16627 16506 16476 16467 16464>,
			<16703 16630 16500 16480 16476 16472>,
			<16707 16630 16499 16485 16484 16480>,
			<16714 16630 16500 16489 16493 16489>,
			<16719 16632 16501 16491 16499 16498>,
			<16723 16638 16503 16491 16504 16508>,
			<16726 16646 16507 16491 16505 16511>,
			<16729 16655 16516 16490 16495 16502>,
			<16731 16663 16528 16486 16482 16488>,
			<16731 16670 16539 16483 16473 16477>,
			<16730 16676 16551 16479 16466 16467>,
			<16729 16678 16562 16478 16466 16466>,
			<16730 16677 16574 16480 16472 16474>,
			<16732 16673 16586 16484 16474 16478>,
			<16741 16659 16596 16487 16474 16479>,
			<16746 16644 16595 16483 16458 16455>,
			<16726 16624 16587 16470 16446 16441>,
			<16740 16634 16594 16481 16461 16463>,
			<16755 16642 16611 16495 16479 16488>,
			<16777 16664 16629 16511 16505 16520>,
			<16802 16691 16657 16539 16540 16553>,
			<16818 16730 16693 16570 16549 16554>,
			<16812 16739 16702 16549 16492 16484>,
			<16801 16712 16682 16520 16472 16470>,
			<16804 16709 16692 16533 16476 16471>,
			<16846 16720 16722 16557 16488 16478>,
			<16846 16720 16722 16557 16488 16478>,
			<16846 16720 16722 16557 16488 16478>;
	};

	qcom,pc-temp-y5-lut {
		qcom,lut-col-legend = <(-10) 0 10 25 40 50>;
		qcom,lut-row-legend = <10000 9800 9600 9400 9200 9000>,
			<8800 8600 8400 8200 8000 7800>,
			<7600 7400 7200 7000 6800 6600>,
			<6400 6200 6000 5800 5600 5400>,
			<5200 5000 4800 4600 4400 4200>,
			<4000 3800 3600 3400 3200 3000>,
			<2800 2600 2400 2200 2000 1800>,
			<1600 1400 1200 1000 900 800>,
			<700 600 500 400 300 200>,
			<100 0>;
		qcom,lut-data = <13332 8712 17045 17640 18275 20910>,
			<13098 10904 17418 18649 19427 20758>,
			<13038 13272 17921 19249 20025 20655>,
			<13111 15368 18430 19532 20206 20591>,
			<13276 16818 18818 19591 20109 20561>,
			<13500 17252 18962 19509 19850 20552>,
			<13974 16835 18970 18934 18932 20456>,
			<14389 16157 18920 18118 17863 20235>,
			<13880 15355 18643 17526 17370 19641>,
			<12405 14291 17971 16992 17040 18543>,
			<12161 13858 17189 16416 16653 17839>,
			<15529 13766 16047 15663 16109 17465>,
			<18454 13951 15349 15207 15791 17093>,
			<17998 17123 15467 15423 16206 16421>,
			<16758 22628 15837 15831 16919 15722>,
			<15690 23277 17071 15825 16829 15716>,
			<14569 19697 20939 15298 15755 16257>,
			<14008 17382 23117 14977 15169 16543>,
			<14353 18240 23221 15765 15263 16212>,
			<14850 19395 23247 17422 15495 15825>,
			<14808 19055 23445 19871 16922 16832>,
			<14342 17303 23841 23578 20406 19871>,
			<13915 15955 23993 24920 21644 20978>,
			<13318 15140 23634 22851 21421 20817>,
			<12789 14449 23262 20667 21064 20635>,
			<12743 13690 23332 21004 20533 20406>,
			<12746 12840 23525 22256 19786 19966>,
			<12755 12529 23608 22646 19032 19304>,
			<12850 12459 23729 22344 17903 17534>,
			<12946 12431 23709 22117 17277 16450>,
			<12960 12580 21072 22457 17603 16515>,
			<12972 12910 17597 23084 18302 16690>,
			<13035 13166 17539 23677 19187 17193>,
			<13287 13414 18924 24780 20461 18529>,
			<13544 13649 19892 25368 21608 19875>,
			<13724 13952 20375 24917 22804 21419>,
			<13863 14263 20642 24174 23592 22441>,
			<13878 14429 20579 23701 22815 21810>,
			<13796 14539 20387 23322 20930 20409>,
			<13677 14605 20067 22719 20559 20280>,
			<13437 14648 17941 21410 21687 21626>,
			<13166 14653 16422 20465 22128 22030>,
			<12902 14548 14814 19996 22130 21894>,
			<13044 14076 14116 19370 20502 21014>,
			<13087 13785 13618 18661 17518 18634>,
			<13430 13562 14184 18898 17802 17786>,
			<13642 13892 13748 17846 17816 16961>,
			<13748 13786 13811 18292 17548 16814>,
			<13919 13851 14033 18410 17929 16408>,
			<14336 14105 14310 18644 17181 15849>,
			<14476 14352 14410 18327 17543 16705>,
			<14104 14227 14247 18913 17848 16745>,
			<14012 14074 14381 19182 18610 16574>,
			<13945 14410 14657 20023 23587 21250>,
			<13945 14410 14657 20023 23587 21250>,
			<13945 14410 14657 20023 23587 21250>;
	};

	qcom,pc-temp-y6-lut {
		qcom,lut-col-legend = <(-10) 0 10 25 40 50>;
		qcom,lut-row-legend = <10000 9800 9600 9400 9200 9000>,
			<8800 8600 8400 8200 8000 7800>,
			<7600 7400 7200 7000 6800 6600>,
			<6400 6200 6000 5800 5600 5400>,
			<5200 5000 4800 4600 4400 4200>,
			<4000 3800 3600 3400 3200 3000>,
			<2800 2600 2400 2200 2000 1800>,
			<1600 1400 1200 1000 900 800>,
			<700 600 500 400 300 200>,
			<100 0>;
		qcom,lut-data = <6373 5660 5283 5076 5032 5024>,
			<6326 5667 5287 5076 5031 5024>,
			<6281 5670 5288 5075 5031 5024>,
			<6238 5670 5288 5075 5032 5024>,
			<6200 5668 5286 5074 5032 5024>,
			<6166 5664 5284 5074 5032 5024>,
			<6135 5654 5279 5074 5032 5025>,
			<6109 5639 5274 5074 5033 5026>,
			<6086 5621 5271 5075 5033 5026>,
			<6066 5601 5268 5076 5035 5027>,
			<6063 5598 5267 5077 5036 5028>,
			<6102 5636 5267 5078 5037 5029>,
			<6135 5668 5267 5080 5039 5030>,
			<6068 5655 5280 5086 5041 5032>,
			<5931 5622 5302 5096 5045 5033>,
			<5885 5588 5299 5098 5048 5035>,
			<5875 5544 5267 5098 5049 5038>,
			<5867 5518 5247 5098 5052 5041>,
			<5858 5515 5245 5106 5059 5047>,
			<5849 5512 5243 5117 5066 5052>,
			<5839 5503 5235 5114 5064 5051>,
			<5828 5482 5214 5094 5056 5047>,
			<5824 5467 5199 5078 5047 5041>,
			<5828 5457 5190 5067 5035 5030>,
			<5834 5451 5185 5060 5027 5021>,
			<5843 5453 5184 5060 5027 5021>,
			<5855 5460 5183 5061 5027 5021>,
			<5870 5470 5182 5062 5028 5022>,
			<5887 5484 5181 5064 5029 5023>,
			<5906 5502 5181 5065 5032 5025>,
			<5926 5523 5182 5067 5035 5027>,
			<5948 5548 5183 5069 5038 5030>,
			<5972 5575 5187 5071 5041 5033>,
			<5999 5605 5196 5073 5043 5037>,
			<6026 5636 5207 5074 5043 5038>,
			<6054 5670 5218 5074 5041 5036>,
			<6081 5707 5232 5074 5037 5032>,
			<6107 5746 5247 5074 5035 5029>,
			<6134 5787 5266 5074 5033 5026>,
			<6159 5829 5284 5075 5033 5026>,
			<6182 5871 5303 5078 5036 5030>,
			<6204 5910 5323 5081 5038 5032>,
			<6230 5946 5347 5085 5039 5032>,
			<6254 5978 5366 5086 5032 5024>,
			<6235 5964 5371 5082 5028 5020>,
			<6299 6035 5415 5094 5038 5031>,
			<6340 6076 5439 5100 5045 5041>,
			<6385 6120 5472 5110 5055 5052>,
			<6431 6165 5509 5122 5067 5063>,
			<6478 6206 5543 5133 5069 5062>,
			<6523 6241 5570 5125 5050 5039>,
			<6580 6270 5601 5121 5045 5036>,
			<6669 6342 5684 5137 5050 5039>,
			<6824 6432 5786 5159 5061 5048>,
			<6824 6432 5786 5159 5061 5048>,
			<6824 6432 5786 5159 5061 5048>;
	};

};
